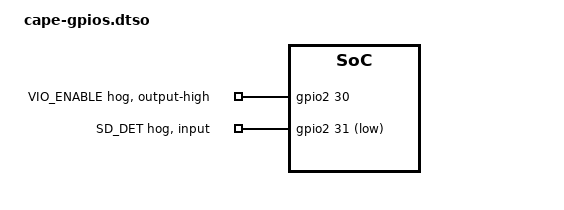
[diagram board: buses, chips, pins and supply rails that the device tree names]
// SPDX-License-Identifier: (GPL-2.0 OR MIT)
/* Copyright (c) 2020-2021 Microchip Technology Inc */

/dts-v1/;
/plugin/;

&{/chosen} {
	overlays {
		MINIMAL-NO-LEDS-CAPE-GATEWARE = "GATEWARE_GIT_VERSION";
	};
};

&gpio2 {
	interrupts = <53>, <53>, <53>, <53>,
		     <53>, <53>, <53>, <53>,
		     <53>, <53>, <53>, <53>,
		     <53>, <53>, <53>, <53>,
		     <53>, <53>, <53>, <53>,
		     <53>, <53>, <53>, <53>,
		     <53>, <53>, <53>, <53>,
		     <53>, <53>, <53>, <53>;
	gpio-line-names = "", "", "",
					"", "", "",
					"", "", "",
					"", "", "",
					"", "", "", "", "",
					"", "", "",	"", "",
					"", "", "", "", "",
					"",
					"M2_W_DISABLE1", "M2_W_DISABLE2",
					"VIO_ENABLE", "SD_DET";
	status = "okay";

	vio_enable {
		gpio-hog;
		gpios = <30 30>;
		output-high;
		line-name = "VIO_ENABLE";
	};

	sd_det {
		gpio-hog;
		gpios = <31 31>;
		input;
		line-name = "SD_DET";
	};
};

&mmuart4 {
	status = "okay";
	symlink = "bone/uart/4";
};
